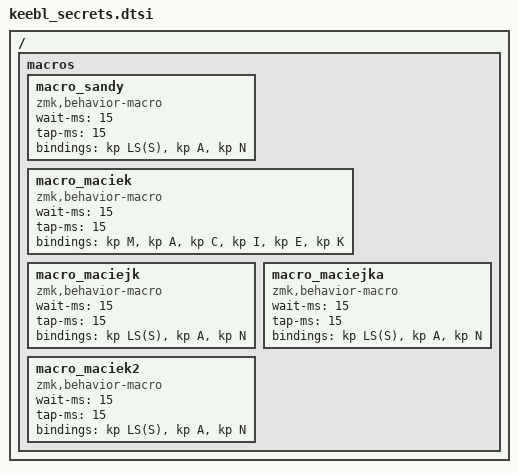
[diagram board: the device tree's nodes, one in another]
/* keebl_secrets.dtsi — SENSITIVE MACROS (real values)
 *
 * THIS FILE IS GITIGNORED — do not commit to a public repository.
 * For a private repository it is safe to commit.
 *
 * Edit the bindings below with your actual passwords and email addresses.
 * See keebl_secrets.dtsi.template for the key-name reference.
 */


/ {
    macros {

        macro_sandy: macro_sandy {          /* Your password */
            compatible = "zmk,behavior-macro";
            #binding-cells = <0>;
            wait-ms = <15>;
            tap-ms  = <15>;
            bindings = <
                &kp LS(S) &kp A &kp N
            >;
        };

        macro_maciek: macro_maciek {        /* Short username */
            compatible = "zmk,behavior-macro";
            #binding-cells = <0>;
            wait-ms = <15>;
            tap-ms  = <15>;
            bindings = <
                &kp M &kp A &kp C &kp I &kp E &kp K
            >;
        };

        macro_maciejk: macro_maciejk {      /* Email 1: firstname.lastname@domain1 */
            compatible = "zmk,behavior-macro";
            #binding-cells = <0>;
            wait-ms = <15>;
            tap-ms  = <15>;
            bindings = <
                &kp LS(S) &kp A &kp N
            >;
        };

        macro_maciejka: macro_maciejka {    /* Email 2: firstname.lastname@domain2 */
            compatible = "zmk,behavior-macro";
            #binding-cells = <0>;
            wait-ms = <15>;
            tap-ms  = <15>;
            bindings = <
                &kp LS(S) &kp A &kp N
            >;
        };

        macro_maciek2: macro_maciek2 {      /* Email 3: short@domain3 */
            compatible = "zmk,behavior-macro";
            #binding-cells = <0>;
            wait-ms = <15>;
            tap-ms  = <15>;
            bindings = <
                &kp LS(S) &kp A &kp N
            >;
        };

    };
};
